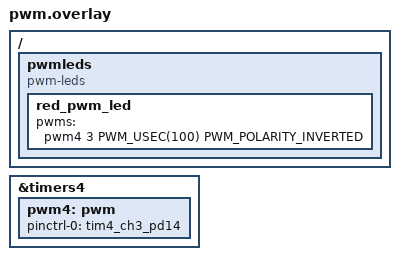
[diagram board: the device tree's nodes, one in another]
&timers4 {
    status = "okay";

    pwm4: pwm {
        status = "okay";
        pinctrl-0 = <&tim4_ch3_pd14>;
        pinctrl-names = "default";
    };
};

/{
    pwmleds: pwmleds {
        compatible = "pwm-leds";
        status = "okay";
        red_pwm_led: red_pwm_led {
            pwms = <&pwm4 3 PWM_USEC(100) PWM_POLARITY_INVERTED>;
        };
    };
};



